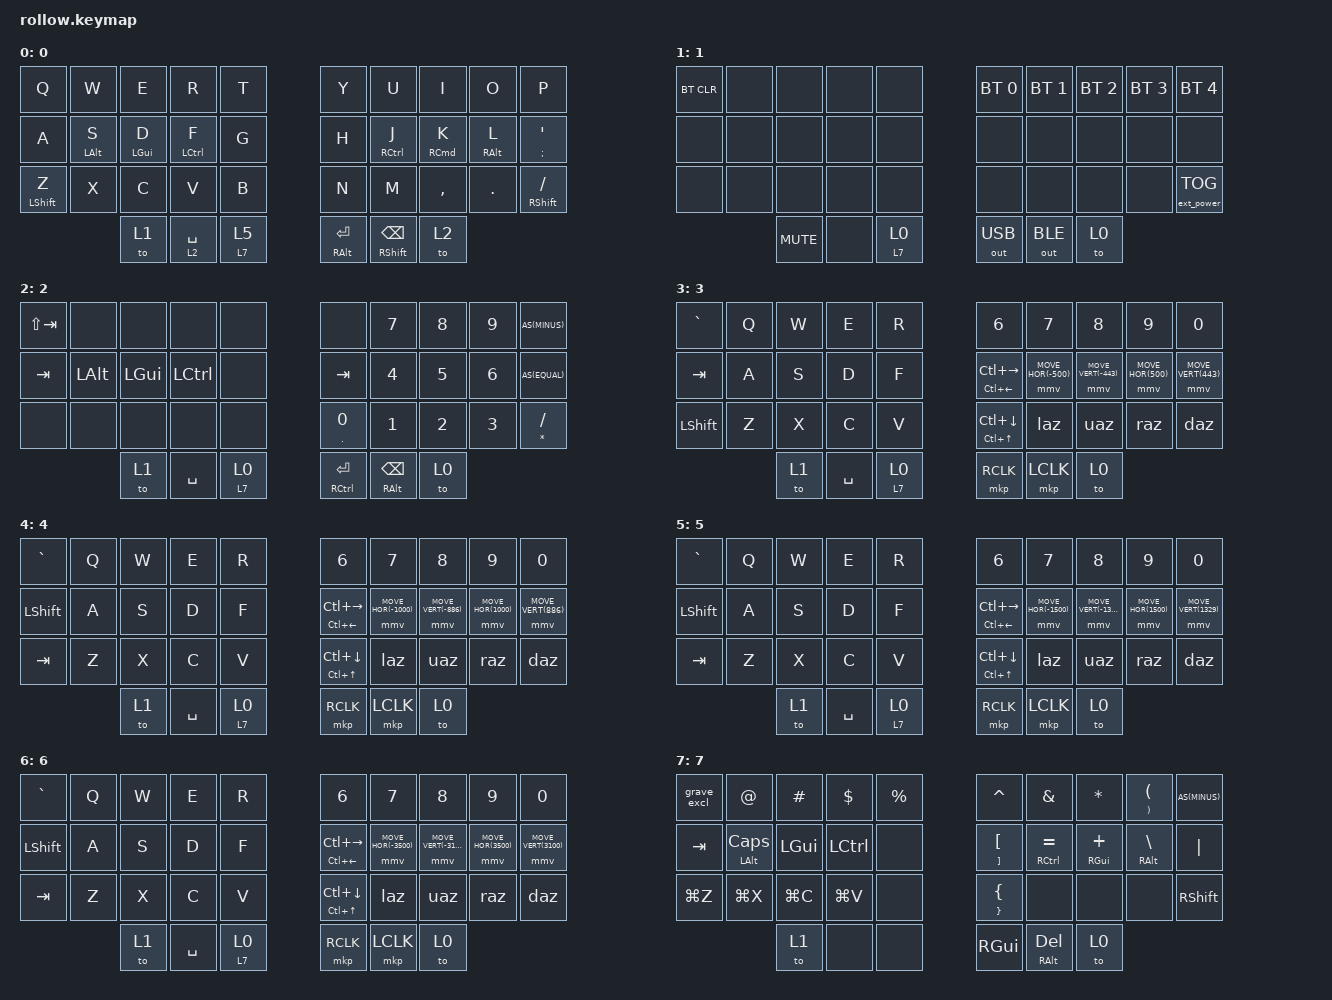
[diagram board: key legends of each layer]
/*
 * Copyright (c) 2020 The ZMK Contributors
 *
 * SPDX-License-Identifier: MIT
 */

#include <behaviors.dtsi>
#include <dt-bindings/zmk/keys.h>
#include <dt-bindings/zmk/bt.h>
#include <dt-bindings/zmk/outputs.h>
#include <dt-bindings/zmk/ext_power.h>
#define AS(keycode) &as LS(keycode) keycode
#include <dt-bindings/zmk/mouse.h>

&mmv {
    time-to-max-speed-ms = <0>;
    acceleration-exponent = <0>;
    delay-ms = <0>;
};

&mwh {
    time-to-max-speed-ms = <0>;
    acceleration-exponent = <0>;
    delay-ms = <0>;
};

/ {
    combos {
        compatible = "zmk,combos";
        combo_escape {
            timeout-ms = <70>;
            key-positions = <0 9>;
            bindings = <&kp ESC>;
            };
        compatible = "zmk,combos";
        combo_rgui {
            timeout-ms = <70>;
            key-positions = <33 34>;
            bindings = <&kp RGUI>;
            };
        };
    behaviors {
        as: auto_shift {
            compatible = "zmk,behavior-hold-tap";
            label = "AUTO_SHIFT";
            #binding-cells = <2>;
            tapping_term_ms = <115>;
            quick_tap_ms = <0>;
            flavor = "tap-preferred";
            bindings = <&kp>, <&kp>;
        };
        tp: tap_mods {
            compatible = "zmk,behavior-hold-tap";
            label = "TAP_MODS";
            #binding-cells = <2>;
            tapping_term_ms = <180>;
            quick-tap-ms = <180>;
            global-quick-tap;
            flavor = "tap-preferred";
            bindings = <&kp>, <&kp>;
        };
        lm: layer_mod {
            compatible = "zmk,behavior-hold-tap";
            label = "LAYER_MOD";
            #binding-cells = <2>;
            tapping_term_ms = <200>;
            flavor = "hold-preferred";
            bindings = <&mo>, <&to>;
        };
        lkm: layer_key_mod {
            compatible = "zmk,behavior-hold-tap";
            label = "LAYER_KEY_MOD";
            #binding-cells = <2>;
            tapping_term_ms = <180>;
            quick_tap_ms = <180>;
            global-quick-tap;
            flavor = "tap-preferred";
            bindings = <&mo>, <&kp>;
        };
        kpmkp: kpmkp {
            compatible = "zmk,behavior-hold-tap";
            label = "KP_MKP";
            #binding-cells = <2>;
            tapping_term_ms = <140>;
            flavor = "tap-preferred";
            bindings = <&kp>, <&mkp>;
        };
        num: num {
            compatible = "zmk,behavior-hold-tap";
            label = "NUMBER_MODS";
            #binding-cells = <2>;
            tapping_term_ms = <125>;
            quick-tap-ms = <999>;
            global-quick-tap;
            flavor = "tap-preferred";
            bindings = <&kp>, <&kp>;
        };
        sh: sh {
            compatible = "zmk,behavior-hold-tap";
            label = "SHIFT_MOD";
            #binding-cells = <2>;
            tapping_term_ms = <110>;
            quick-tap-ms = <0>;
            global-quick-tap;
            flavor = "balanced";
            bindings = <&kp>, <&kp>;
        };
        alt_bd: alt_bd {
            compatible = "zmk,behavior-mod-morph";
            label = "ALT_BACKSPACE_DEL";
            #binding-cells = <0>;
            bindings = <&tp RALT BSPC>, <&kp DEL>;
            mods = <(MOD_LSFT)>;
        };
        grave_excl: grave_excl {
            compatible = "zmk,behavior-mod-morph";
            label = "GRAVE_EXCL";
            #binding-cells = <0>;
            bindings = <&kp EXCL>, <&as GRAVE TILDE>;
            mods = <(MOD_RGUI)>;
            keep-mods = <(MOD_RGUI)>;
        };
        laz: laz {
            compatible = "zmk,behavior-mod-morph";
            label = "LEFT_ARROWZ";
            #binding-cells = <0>;
            bindings = <&kp LEFT>, <&kp LG(LEFT)>;
            mods = <(MOD_LSFT)>;
        };
        raz: raz {
            compatible = "zmk,behavior-mod-morph";
            label = "RIGHT_ARROWZ";
            #binding-cells = <0>;
            bindings = <&kp RIGHT>, <&kp LG(RIGHT)>;
            mods = <(MOD_LSFT)>;
        };
        uaz: uaz {
            compatible = "zmk,behavior-mod-morph";
            label = "UP_ARROWZ";
            #binding-cells = <0>;
            bindings = <&kp UP>, <&kp PG_UP>;
            mods = <(MOD_LSFT)>;
        };
        daz: daz {
            compatible = "zmk,behavior-mod-morph";
            label = "DOWN_ARROWZ";
            #binding-cells = <0>;
            bindings = <&kp DOWN>, <&kp PG_DN>;
            mods = <(MOD_LSFT)>;
        };
        left_backspace: left_backspace {
            compatible = "zmk,behavior-mod-morph";
            label = "LEFT_BACKSPACE";
            #binding-cells = <0>;
            bindings = <&kp LEFT>, <&kp LA(BSPC)>;
            mods = <(MOD_LSFT|MOD_RSFT)>;
        };
        right_delete: right_delete {
            compatible = "zmk,behavior-mod-morph";
            label = "RIGHT_DELETE";
            #binding-cells = <0>;
            bindings = <&kp RIGHT>, <&kp LA(DEL)>;
            mods = <(MOD_LSFT|MOD_RSFT)>;
        };
        move_right: move_right {
            compatible = "zmk,behavior-mod-morph";
            label = "MOVE_RIGHT";
            #binding-cells = <0>;
            bindings = <&right_delete>, <&kp LA(RIGHT)>;
            mods = <(MOD_RALT|MOD_LALT)>;
        };
        move_left: move_left {
            compatible = "zmk,behavior-mod-morph";
            label = "SCROLL_LEFT";
            #binding-cells = <0>;
            bindings = <&left_backspace>, <&kp LA(LEFT)>;
            mods = <(MOD_RALT|MOD_LALT)>;
        };
        scroll_erase: scroll_erase {
            compatible = "zmk,behavior-sensor-rotate";
            label = "SCROLL_ERASE";
            #sensor-binding-cells = <0>;
            bindings = <&move_right>, <&move_left>;
        };
        wheel_down_extra_slow: wheel_down_extra_slow {
            compatible = "zmk,behavior-mod-morph";
            label = "WHEEL_DOWN_EXTRA_SLOW";
            #binding-cells = <0>;
            bindings = <&mwh SCROLL_VERT(-200) >, <&mwh SCROLL_HOR(-200)>;
            mods = <(MOD_LSFT)>;
        };
        wheel_up_extra_slow: wheel_up_extra_slow {
            compatible = "zmk,behavior-mod-morph";
            label = "WHEEL_UP_EXTRA_SLOW";
            #binding-cells = <0>;
            bindings = <&mwh SCROLL_VERT(200)>, <&mwh SCROLL_HOR(200)>;
            mods = <(MOD_LSFT)>;
        };
        scroll_mouse_extra_slow: scroll_mouse_extra_slow {
            compatible = "zmk,behavior-sensor-rotate";
            label = "SCROLL_MOUSE_EXTRA_SLOW";
            #sensor-binding-cells = <0>;
            bindings = <&wheel_up_extra_slow>, <&wheel_down_extra_slow>;
        };
        wheel_down_slow: wheel_down_slow {
            compatible = "zmk,behavior-mod-morph";
            label = "WHEEL_DOWN_SLOW";
            #binding-cells = <0>;
            bindings = <&mwh SCROLL_VERT(-400) >, <&mwh SCROLL_HOR(-400)>;
            mods = <(MOD_LSFT)>;
        };
        wheel_up_slow: wheel_up_slow {
            compatible = "zmk,behavior-mod-morph";
            label = "WHEEL_UP_SLOW";
            #binding-cells = <0>;
            bindings = <&mwh SCROLL_VERT(400)>, <&mwh SCROLL_HOR(400)>;
            mods = <(MOD_LSFT)>;
        };
        scroll_mouse_slow: scroll_mouse_slow {
            compatible = "zmk,behavior-sensor-rotate";
            label = "SCROLL_MOUSE_SLOW";
            #sensor-binding-cells = <0>;
            bindings = <&wheel_up_slow>, <&wheel_down_slow>;
        };
        wheel_down: wheel_down {
            compatible = "zmk,behavior-mod-morph";
            label = "WHEEL_DOWN";
            #binding-cells = <0>;
            bindings = <&mwh SCROLL_VERT(-800) >, <&mwh SCROLL_HOR(-800)>;
            mods = <(MOD_LSFT)>;
        };
        wheel_up: wheel_up {
            compatible = "zmk,behavior-mod-morph";
            label = "WHEEL_UP";
            #binding-cells = <0>;
            bindings = <&mwh SCROLL_VERT(800)>, <&mwh SCROLL_HOR(800)>;
            mods = <(MOD_LSFT)>;
        };
        scroll_mouse: scroll_mouse {
            compatible = "zmk,behavior-sensor-rotate";
            label = "SCROLL_MOUSE";
            #sensor-binding-cells = <0>;
            bindings = <&wheel_up>, <&wheel_down>;
        };
        wheel_down_fast: wheel_down_fast {
            compatible = "zmk,behavior-mod-morph";
            label = "WHEEL_DOWN_FAST";
            #binding-cells = <0>;
            bindings = <&mwh SCROLL_VERT(-1600) >, <&mwh SCROLL_HOR(-1600)>;
            mods = <(MOD_LSFT)>;
        };
        wheel_up_fast: wheel_up_fast {
            compatible = "zmk,behavior-mod-morph";
            label = "WHEEL_UP_FAST";
            #binding-cells = <0>;
            bindings = <&mwh SCROLL_VERT(1600)>, <&mwh SCROLL_HOR(1600)>;
            mods = <(MOD_LSFT)>;
        };
        scroll_mouse_fast: scroll_mouse_fast {
            compatible = "zmk,behavior-sensor-rotate";
            label = "SCROLL_MOUSE_FAST";
            #sensor-binding-cells = <0>;
            bindings = <&wheel_up_fast>, <&wheel_down_fast>;
        };
        scroll_layer43: scroll_layer43 {
            compatible = "zmk,behavior-sensor-rotate";
            label = "SCROLL_LAYER43";
            #sensor-binding-cells = <0>;
            bindings = <&to 4>, <&to 3>;
        };
        scroll_layer53: scroll_layer53 {
            compatible = "zmk,behavior-sensor-rotate";
            label = "SCROLL_LAYER53";
            #sensor-binding-cells = <0>;
            bindings = <&to 5>, <&to 3>;
        };
        scroll_layer64: scroll_layer64 {
            compatible = "zmk,behavior-sensor-rotate";
            label = "SCROLL_LAYER64";
            #sensor-binding-cells = <0>;
            bindings = <&to 6>, <&to 4>;
        };
        scroll_layer65: scroll_layer65 {  
            compatible = "zmk,behavior-sensor-rotate";
            label = "SCROLL_LAYER65";
            #sensor-binding-cells = <0>;
            bindings = <&to 6>, <&to 5>;
        };
};
        keymap {
                compatible = "zmk,keymap";
 
                0 {
                        bindings = <
&kp Q &kp W &kp E &kp R &kp T                         &kp Y &kp U &kp I &kp O &kp P
&kp A &tp LALT S &tp LGUI D &tp LCTL F &kp G          &kp H &tp RCTL J &tp RCMD K &tp RALT L &as SEMI APOS
&sh LSHIFT Z &kp X &kp C &kp V &kp B                  &kp N &kp M &kp COMMA &kp DOT &sh RSHIFT FSLH
     &to 1 &lkm 2 SPACE &lm 7 5                       &tp RALT RET &tp RSHIFT BSPC &to 2
                        >;

 sensor-bindings = <&scroll_erase &inc_dec_kp DOWN UP>;
                };

                1 { 
                 bindings = <
&bt BT_CLR &none &none &none &none       &bt BT_SEL 0 &bt BT_SEL 1 &bt BT_SEL 2 &bt BT_SEL 3 &bt BT_SEL 4
&none &none &none &none &none            &none &none &none &none &none 
&none &none &none &none &none            &none &none &none &none &ext_power EP_TOG
       &kp K_MUTE &none &lm 7 0            &out OUT_USB &out OUT_BLE &to 0
                         >;
   
sensor-bindings = <&inc_dec_kp C_VOL_UP C_VOL_DN &inc_dec_kp C_BRI_UP C_BRI_DN>;
                };
                
                2 {
                        bindings = <
&kp LS(TAB) &none &none &none &none                                       &none &kp N7 &kp N8 &kp N9 AS(MINUS) 
&kp TAB &kp LALT &kp LGUI &kp LCTL &none                              &kp TAB &kp N4 &kp N5 &kp N6 AS(EQUAL)
&none &none &none &none &none                                       &as DOT N0 &kp N1 &kp N2 &kp N3 &as STAR SLASH   
        &to 1 &kp SPACE &lm 7 0                                       &tp RCTL RET &tp RALT BSPC &to 0
                        >;

sensor-bindings = <&scroll_erase &inc_dec_kp DOWN UP>;
                };
                
                3 {
                        bindings = <
&kp GRAVE &kp Q &kp W &kp E &kp R           &kp N6 &kp N7 &kp N8 &kp N9 &kp N0
&kp TAB &kp A &kp S &kp D &kp F             &as LC(LEFT) LC(RIGHT) &mmv MOVE_HOR(-500) &mmv MOVE_VERT(-443) &mmv MOVE_HOR(500) &mmv MOVE_VERT(443)
&kp LSHIFT &kp Z &kp X &kp C &kp V          &as LC(UP) LC(DOWN) &laz &uaz &raz &daz
        &to 1 &kp SPACE &lm 7 0               &mkp RCLK &mkp LCLK &to 0
                        >;

sensor-bindings = <&scroll_mouse_extra_slow &scroll_layer43>;
                };
                
                4 {
                        bindings = <
&kp GRAVE &kp Q &kp W &kp E &kp R        &kp N6 &kp N7 &kp N8 &kp N9 &kp N0
&kp LSHIFT &kp A &kp S &kp D &kp F          &as LC(LEFT) LC(RIGHT) &mmv MOVE_HOR(-1000) &mmv MOVE_VERT(-886) &mmv MOVE_HOR(1000) &mmv MOVE_VERT(886)
&kp TAB &kp Z &kp X &kp C &kp V       &as LC(UP) LC(DOWN) &laz &uaz &raz &daz
        &to 1 &kp SPACE &lm 7 0           &mkp RCLK &mkp LCLK &to 0 
                        >;

sensor-bindings = <&scroll_mouse_slow &scroll_layer53>;
                };
                             
                5 {
                        bindings = <
&kp GRAVE &kp Q &kp W &kp E &kp R                       &kp N6 &kp N7 &kp N8 &kp N9 &kp N0
&kp LSHIFT &kp A &kp S &kp D &kp F           &as LC(LEFT) LC(RIGHT) &mmv MOVE_HOR(-1500) &mmv MOVE_VERT(-1329) &mmv MOVE_HOR(1500) &mmv MOVE_VERT(1329)
&kp TAB &kp Z &kp X &kp C &kp V                       &as LC(UP) LC(DOWN) &laz &uaz &raz &daz
        &to 1 &kp SPACE &lm 7 0                          &mkp RCLK &mkp LCLK &to 0 
                         >;

sensor-bindings = <&scroll_mouse &scroll_layer64>;
                };
                
                6 {
                        bindings = <
&kp GRAVE &kp Q &kp W &kp E &kp R        &kp N6 &kp N7 &kp N8 &kp N9 &kp N0
&kp LSHIFT &kp A &kp S &kp D &kp F          &as LC(LEFT) LC(RIGHT) &mmv MOVE_HOR(-3500) &mmv MOVE_VERT(-3100) &mmv MOVE_HOR(3500) &mmv MOVE_VERT(3100)
&kp TAB &kp Z &kp X &kp C &kp V       &as LC(UP) LC(DOWN) &laz &uaz &raz &daz
        &to 1 &kp SPACE &lm 7 0          &mkp RCLK &mkp LCLK &to 0 
                         >;

sensor-bindings = <&scroll_mouse_fast &scroll_layer65>;
                };

                7 {
                        bindings = <
&grave_excl &kp AT &kp HASH &kp DOLLAR &kp PERCENT                      &kp CARET &kp AMPS &kp STAR &as RPAR LPAR AS(MINUS)
&kp TAB &tp LALT CAPS &kp LGUI &kp LCTRL &none                       &as RBKT LBKT &tp RCTRL EQUAL &tp RGUI PLUS &tp RALT BSLH &kp PIPE 
&kp LG(Z) &kp LG(X) &kp LG(C) &kp LG(V) &none                        &as RBRC LBRC &none &none &none &kp RSHIFT
            &to 1 &none &none                                        &kp RGUI &tp RALT DEL &to 0
                        >;
   
sensor-bindings = <&scroll_erase &inc_dec_kp PG_DN PG_UP>;
                };
        };
};
